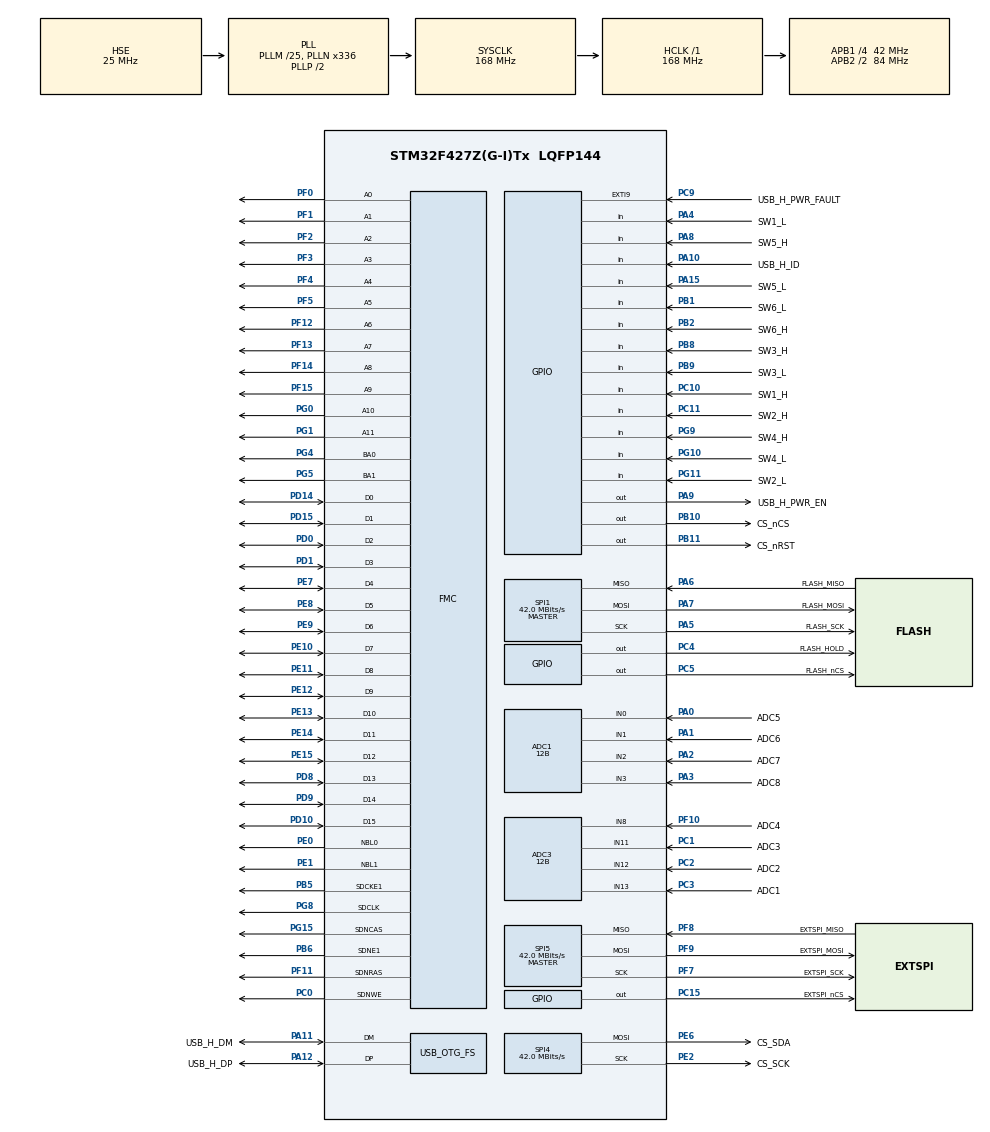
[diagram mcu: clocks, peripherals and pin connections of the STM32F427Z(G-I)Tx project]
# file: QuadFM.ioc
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ADC1.Channel-0\#ChannelRegularConversion=ADC_CHANNEL_0
ADC1.ClockPrescaler=ADC_CLOCK_SYNC_PCLK_DIV8
ADC1.ContinuousConvMode=DISABLE
ADC1.DMAContinuousRequests=DISABLE
ADC1.DataAlign=ADC_DATAALIGN_RIGHT
ADC1.DiscontinuousConvMode=DISABLE
ADC1.EOCSelection=ADC_EOC_SINGLE_CONV
ADC1.EnableAnalogWatchDog=false
ADC1.ExternalTrigConv=ADC_SOFTWARE_START
ADC1.ExternalTrigConvEdge=ADC_EXTERNALTRIGCONVEDGE_NONE
ADC1.InjNumberOfConversion=0
ADC1.NbrOfConversion=1
ADC1.NbrOfConversionFlag=1
ADC1.Rank-0\#ChannelRegularConversion=1
ADC1.Resolution=ADC_RESOLUTION_12B
ADC1.SamplingTime-0\#ChannelRegularConversion=ADC_SAMPLETIME_3CYCLES
ADC1.ScanConvMode=DISABLE
ADC1.master=1
ADC3.Channel-31\#ChannelRegularConversion=ADC_CHANNEL_12
ADC3.Channel-32\#ChannelRegularConversion=ADC_CHANNEL_8
ADC3.Channel-33\#ChannelRegularConversion=ADC_CHANNEL_11
ADC3.Channel-34\#ChannelRegularConversion=ADC_CHANNEL_13
ADC3.ClockPrescaler=ADC_CLOCK_SYNC_PCLK_DIV8
ADC3.ContinuousConvMode=ENABLE
ADC3.DMAContinuousRequests=ENABLE
ADC3.DataAlign=ADC_DATAALIGN_RIGHT
ADC3.DiscontinuousConvMode=DISABLE
ADC3.EOCSelection=ADC_EOC_SEQ_CONV
ADC3.EnableAnalogWatchDog=false
ADC3.ExternalTrigConv=ADC_SOFTWARE_START
ADC3.ExternalTrigConvEdge=ADC_EXTERNALTRIGCONVEDGE_NONE
ADC3.InjNumberOfConversion=0
ADC3.NbrOfConversion=4
ADC3.NbrOfConversionFlag=1
ADC3.Rank-31\#ChannelRegularConversion=1
ADC3.Rank-32\#ChannelRegularConversion=2
ADC3.Rank-33\#ChannelRegularConversion=3
ADC3.Rank-34\#ChannelRegularConversion=4
ADC3.Resolution=ADC_RESOLUTION_12B
ADC3.SamplingTime-31\#ChannelRegularConversion=ADC_SAMPLETIME_144CYCLES
ADC3.SamplingTime-32\#ChannelRegularConversion=ADC_SAMPLETIME_144CYCLES
ADC3.SamplingTime-33\#ChannelRegularConversion=ADC_SAMPLETIME_144CYCLES
ADC3.SamplingTime-34\#ChannelRegularConversion=ADC_SAMPLETIME_144CYCLES
ADC3.ScanConvMode=ENABLE
Dma.ADC1.0.Direction=DMA_PERIPH_TO_MEMORY
Dma.ADC1.0.FIFOMode=DMA_FIFOMODE_DISABLE
Dma.ADC1.0.Instance=DMA2_Stream4
Dma.ADC1.0.MemDataAlignment=DMA_MDATAALIGN_HALFWORD
Dma.ADC1.0.MemInc=DMA_MINC_ENABLE
Dma.ADC1.0.Mode=DMA_NORMAL
Dma.ADC1.0.PeriphDataAlignment=DMA_PDATAALIGN_HALFWORD
Dma.ADC1.0.PeriphInc=DMA_PINC_DISABLE
Dma.ADC1.0.Priority=DMA_PRIORITY_LOW
Dma.ADC3.1.Direction=DMA_PERIPH_TO_MEMORY
Dma.ADC3.1.FIFOMode=DMA_FIFOMODE_DISABLE
Dma.ADC3.1.Instance=DMA2_Stream0
Dma.ADC3.1.MemDataAlignment=DMA_MDATAALIGN_HALFWORD
Dma.ADC3.1.MemInc=DMA_MINC_ENABLE
Dma.ADC3.1.Mode=DMA_CIRCULAR
Dma.ADC3.1.PeriphDataAlignment=DMA_PDATAALIGN_HALFWORD
Dma.ADC3.1.PeriphInc=DMA_PINC_DISABLE
Dma.ADC3.1.Priority=DMA_PRIORITY_LOW
Dma.Request0=ADC1
Dma.Request1=ADC3
FMC.CASLatency1=FMC_SDRAM_CAS_LATENCY_3
FMC.ExitSelfRefreshDelay1=6
FMC.LoadToActiveDelay1=2
FMC.RCDDelay1=2
FMC.RPDelay1=2
FMC.RPDelay2=2
FMC.ReadBurst1=FMC_SDRAM_RBURST_ENABLE
FMC.ReadBurst2=FMC_SDRAM_RBURST_ENABLE
FMC.ReadPipeDelay1=FMC_SDRAM_RPIPE_DELAY_0
FMC.RowCycleDelay1=6
FMC.RowCycleDelay2=6
FMC.SDClockPeriod1=FMC_SDRAM_CLOCK_PERIOD_2
FMC.SDClockPeriod2=FMC_SDRAM_CLOCK_PERIOD_2
FMC.SelfRefreshTime1=4
FMC.WriteRecoveryTime1=2
Mcu.Family=STM32F4
Mcu.Name=STM32F427Z(G-I)Tx
Mcu.Package=LQFP144
NVIC.DMA2_Stream0_IRQn=true\:0\:0\:true\:false\:true\:true
NVIC.DMA2_Stream4_IRQn=true\:5\:0\:true\:false\:true\:true
NVIC.EXTI9_5_IRQn=true\:0\:0\:false\:false\:true\:true
NVIC.OTG_FS_IRQn=true\:0\:0\:false\:false\:true\:true
NVIC.PriorityGroup=NVIC_PRIORITYGROUP_4
PA0/WKUP.GPIO_Label=ADC5
PA0/WKUP.Signal=ADCx_IN0
PA1.GPIO_Label=ADC6
PA1.Signal=ADCx_IN1
PA10.GPIO_Label=USB_H_ID
PA10.GPIO_PuPd=GPIO_PULLUP
PA10.Signal=GPIO_Input
PA11.GPIO_Label=USB_H_DM
PA11.Mode=Host_Only
PA11.Signal=USB_OTG_FS_DM
PA12.GPIO_Label=USB_H_DP
PA12.Mode=Host_Only
PA12.Signal=USB_OTG_FS_DP
PA13.Mode=Trace_Asynchronous_SW
PA13.Signal=SYS_JTMS-SWDIO
PA14.Mode=Trace_Asynchronous_SW
PA14.Signal=SYS_JTCK-SWCLK
PA15.GPIO_Label=SW5_L
PA15.GPIO_Mode=GPIO_MODE_INPUT
PA15.GPIO_PuPd=GPIO_PULLUP
PA15.Signal=GPIO_Input
PA2.GPIO_Label=ADC7
PA2.Signal=ADCx_IN2
PA3.GPIO_Label=ADC8
PA3.Signal=ADCx_IN3
PA4.GPIO_Label=SW1_L
PA4.GPIO_Mode=GPIO_MODE_INPUT
PA4.GPIO_PuPd=GPIO_PULLUP
PA4.Signal=GPIO_Input
PA5.GPIO_Label=FLASH_SCK
PA5.Mode=Full_Duplex_Master
PA5.Signal=SPI1_SCK
PA6.GPIO_Label=FLASH_MISO
PA6.Mode=Full_Duplex_Master
PA6.Signal=SPI1_MISO
PA7.GPIO_Label=FLASH_MOSI
PA7.Mode=Full_Duplex_Master
PA7.Signal=SPI1_MOSI
PA8.GPIO_Label=SW5_H
PA8.GPIO_Mode=GPIO_MODE_INPUT
PA8.GPIO_PuPd=GPIO_PULLUP
PA8.Signal=GPIO_Input
PA9.GPIO_Label=USB_H_PWR_EN
PA9.PinState=GPIO_PIN_SET
PA9.Signal=GPIO_Output
PB1.GPIO_Label=SW6_L
PB1.GPIO_PuPd=GPIO_PULLUP
PB1.Signal=GPIO_Input
PB10.GPIO_Label=CS_nCS
PB10.Signal=GPIO_Output
PB11.GPIO_Label=CS_nRST
PB11.Signal=GPIO_Output
PB2/BOOT1.GPIO_Label=SW6_H
PB2/BOOT1.GPIO_PuPd=GPIO_PULLUP
PB2/BOOT1.Signal=GPIO_Input
PB3.Mode=Trace_Asynchronous_SW
PB3.Signal=SYS_JTDO-SWO
PB5.Mode=SdramChipSelect2_1
PB5.Signal=FMC_SDCKE1
PB6.Mode=SdramChipSelect2_1
PB6.Signal=FMC_SDNE1
PB8.GPIO_Label=SW3_H
PB8.GPIO_Mode=GPIO_MODE_INPUT
PB8.GPIO_PuPd=GPIO_PULLUP
PB8.Signal=GPIO_Input
PB9.GPIO_Label=SW3_L
PB9.GPIO_Mode=GPIO_MODE_INPUT
PB9.GPIO_PuPd=GPIO_PULLUP
PB9.Signal=GPIO_Input
PC0.Signal=FMC_SDNWE
PC1.GPIO_Label=ADC3
PC1.Signal=ADCx_IN11
PC10.GPIO_Label=SW1_H
PC10.GPIO_Mode=GPIO_MODE_INPUT
PC10.GPIO_PuPd=GPIO_PULLUP
PC10.Signal=GPIO_Input
PC11.GPIO_Label=SW2_H
PC11.GPIO_Mode=GPIO_MODE_INPUT
PC11.GPIO_PuPd=GPIO_PULLUP
PC11.Signal=GPIO_Input
PC15/OSC32_OUT.GPIO_Label=EXTSPI_nCS
PC15/OSC32_OUT.Signal=GPIO_Output
PC2.GPIO_Label=ADC2
PC2.Signal=ADCx_IN12
PC3.GPIO_Label=ADC1
PC3.Signal=ADCx_IN13
PC4.GPIO_Label=FLASH_HOLD
PC4.Signal=GPIO_Output
PC5.GPIO_Label=FLASH_nCS
PC5.Signal=GPIO_Output
PC9.GPIO_Label=USB_H_PWR_FAULT
PC9.GPIO_ModeDefaultEXTI=GPIO_MODE_IT_FALLING
PC9.GPIO_PuPd=GPIO_PULLUP
PC9.Signal=GPXTI9
PD0.Signal=FMC_D2_DA2
PD1.Signal=FMC_D3_DA3
PD10.Signal=FMC_D15_DA15
PD14.Signal=FMC_D0_DA0
PD15.Signal=FMC_D1_DA1
PD8.Signal=FMC_D13_DA13
PD9.Signal=FMC_D14_DA14
PE0.Signal=FMC_NBL0
PE1.Signal=FMC_NBL1
PE10.Signal=FMC_D7_DA7
PE11.Signal=FMC_D8_DA8
PE12.Signal=FMC_D9_DA9
PE13.Signal=FMC_D10_DA10
PE14.Signal=FMC_D11_DA11
PE15.Signal=FMC_D12_DA12
PE2.GPIO_Label=CS_SCK
PE2.Mode=TX_Only_Simplex_Unidirect_Master
PE2.Signal=SPI4_SCK
PE6.GPIO_Label=CS_SDA
PE6.Mode=TX_Only_Simplex_Unidirect_Master
PE6.Signal=SPI4_MOSI
PE7.Signal=FMC_D4_DA4
PE8.Signal=FMC_D5_DA5
PE9.Signal=FMC_D6_DA6
PF0.Signal=FMC_A0
PF1.Signal=FMC_A1
PF10.GPIO_Label=ADC4
PF10.Mode=IN8
PF10.Signal=ADC3_IN8
PF11.Signal=FMC_SDNRAS
PF12.Signal=FMC_A6
PF13.Signal=FMC_A7
PF14.Signal=FMC_A8
PF15.Signal=FMC_A9
PF2.Signal=FMC_A2
PF3.Signal=FMC_A3
PF4.Signal=FMC_A4
PF5.Signal=FMC_A5
PF7.GPIO_Label=EXTSPI_SCK
PF7.Mode=Full_Duplex_Master
PF7.Signal=SPI5_SCK
PF8.GPIO_Label=EXTSPI_MISO
PF8.Mode=Full_Duplex_Master
PF8.Signal=SPI5_MISO
PF9.GPIO_Label=EXTSPI_MOSI
PF9.Mode=Full_Duplex_Master
PF9.Signal=SPI5_MOSI
PG0.Signal=FMC_A10
PG1.Signal=FMC_A11
PG10.GPIO_Label=SW4_L
PG10.GPIO_Mode=GPIO_MODE_INPUT
PG10.GPIO_PuPd=GPIO_PULLUP
PG10.Signal=GPIO_Input
PG11.GPIO_Label=SW2_L
PG11.GPIO_Mode=GPIO_MODE_INPUT
PG11.GPIO_PuPd=GPIO_PULLUP
PG11.Signal=GPIO_Input
PG15.Signal=FMC_SDNCAS
PG4.Signal=FMC_A14_BA0
PG5.Signal=FMC_A15_BA1
PG8.Signal=FMC_SDCLK
PG9.GPIO_Label=SW4_H
PG9.GPIO_Mode=GPIO_MODE_INPUT
PG9.GPIO_PuPd=GPIO_PULLUP
PG9.Signal=GPIO_Input
PH0/OSC_IN.Mode=HSE-External-Oscillator
PH0/OSC_IN.Signal=RCC_OSC_IN
PH1/OSC_OUT.Mode=HSE-External-Oscillator
PH1/OSC_OUT.Signal=RCC_OSC_OUT
ProjectManager.HeapSize=0x200
ProjectManager.StackSize=0x400
ProjectManager.TargetToolchain=MDK-ARM V5
RCC.48MHZClocksFreq_Value=48000000
RCC.AHBFreq_Value=168000000
RCC.APB1CLKDivider=RCC_HCLK_DIV4
RCC.APB1Freq_Value=42000000
RCC.APB1TimFreq_Value=84000000
RCC.APB2CLKDivider=RCC_HCLK_DIV2
RCC.APB2Freq_Value=84000000
RCC.APB2TimFreq_Value=168000000
RCC.CortexFreq_Value=168000000
RCC.HCLKFreq_Value=168000000
RCC.HSE_VALUE=25000000
RCC.HSI_VALUE=16000000
RCC.LSE_VALUE=32768
RCC.PLLM=25
RCC.PLLN=336
RCC.PLLQ=7
RCC.PLLSAIN=100
RCC.SYSCLKFreq_VALUE=168000000
RCC.SYSCLKSource=RCC_SYSCLKSOURCE_PLLCLK
RCC.USBFreq_Value=48000000
RCC.VCOOutputFreq_Value=336000000
SH.ADCx_IN0.0=ADC1_IN0,IN0
SH.ADCx_IN1.0=ADC1_IN1,IN1
SH.ADCx_IN11.0=ADC3_IN11,IN11
SH.ADCx_IN12.0=ADC3_IN12,IN12
SH.ADCx_IN13.0=ADC3_IN13,IN13
SH.ADCx_IN2.0=ADC1_IN2,IN2
SH.ADCx_IN3.0=ADC1_IN3,IN3
SH.FMC_A0.0=FMC_A0,12b-sda1
SH.FMC_A1.0=FMC_A1,12b-sda1
SH.FMC_A10.0=FMC_A10,12b-sda1
SH.FMC_A11.0=FMC_A11,12b-sda1
SH.FMC_A14_BA0.0=FMC_BA0,FourSdramBanks1
SH.FMC_A15_BA1.0=FMC_BA1,FourSdramBanks1
SH.FMC_A2.0=FMC_A2,12b-sda1
SH.FMC_A3.0=FMC_A3,12b-sda1
SH.FMC_A4.0=FMC_A4,12b-sda1
SH.FMC_A5.0=FMC_A5,12b-sda1
SH.FMC_A6.0=FMC_A6,12b-sda1
SH.FMC_A7.0=FMC_A7,12b-sda1
SH.FMC_A8.0=FMC_A8,12b-sda1
SH.FMC_A9.0=FMC_A9,12b-sda1
SH.FMC_D0_DA0.0=FMC_D0,sd-16b-d1
SH.FMC_D10_DA10.0=FMC_D10,sd-16b-d1
SH.FMC_D11_DA11.0=FMC_D11,sd-16b-d1
SH.FMC_D12_DA12.0=FMC_D12,sd-16b-d1
SH.FMC_D13_DA13.0=FMC_D13,sd-16b-d1
SH.FMC_D14_DA14.0=FMC_D14,sd-16b-d1
SH.FMC_D15_DA15.0=FMC_D15,sd-16b-d1
SH.FMC_D1_DA1.0=FMC_D1,sd-16b-d1
SH.FMC_D2_DA2.0=FMC_D2,sd-16b-d1
SH.FMC_D3_DA3.0=FMC_D3,sd-16b-d1
SH.FMC_D4_DA4.0=FMC_D4,sd-16b-d1
SH.FMC_D5_DA5.0=FMC_D5,sd-16b-d1
SH.FMC_D6_DA6.0=FMC_D6,sd-16b-d1
SH.FMC_D7_DA7.0=FMC_D7,sd-16b-d1
SH.FMC_D8_DA8.0=FMC_D8,sd-16b-d1
SH.FMC_D9_DA9.0=FMC_D9,sd-16b-d1
SH.FMC_NBL0.0=FMC_NBL0,Sd2ByteEnable1
SH.FMC_NBL1.0=FMC_NBL1,Sd2ByteEnable1
SH.FMC_SDCLK.0=FMC_SDCLK,12b-sda1
SH.FMC_SDNCAS.0=FMC_SDNCAS,12b-sda1
SH.FMC_SDNRAS.0=FMC_SDNRAS,12b-sda1
SH.FMC_SDNWE.0=FMC_SDNWE,12b-sda1
SPI1.CalculateBaudRate=42.0 MBits/s
SPI1.Direction=SPI_DIRECTION_2LINES
SPI1.Mode=SPI_MODE_MASTER
SPI1.VirtualType=VM_MASTER
SPI4.CalculateBaudRate=42.0 MBits/s
SPI4.Direction=SPI_DIRECTION_2LINES
SPI4.Mode=SPI_MODE_MASTER
SPI4.VirtualType=VM_MASTER
SPI5.CalculateBaudRate=42.0 MBits/s
SPI5.Direction=SPI_DIRECTION_2LINES
SPI5.Mode=SPI_MODE_MASTER
SPI5.VirtualType=VM_MASTER
USB_HOST.USBH_HandleTypeDef-AUDIO_FS=hUsbHostFS
USB_HOST.VirtualModeFS=Audio
USB_OTG_FS.VirtualMode=Host_Only
USB_OTG_FS.phy_itface=HCD_PHY_EMBEDDED
VP_USB_HOST_VS_USB_HOST_AUDIO_FS.Mode=AUDIO_FS
board=QuadFM

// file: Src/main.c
/**
  ******************************************************************************
  * File Name          : main.c
  * Description        : Main program body
  ******************************************************************************
  * This notice applies to any and all portions of this file
  * that are not between comment pairs USER CODE BEGIN and
  * USER CODE END. Other portions of this file, whether
  * inserted by the user or by software development tools
  * are owned by their respective copyright owners.
  *
  * Copyright (c) 2017 STMicroelectronics International N.V.
  * All rights reserved.
  *
  * Redistribution and use in source and binary forms, with or without
  * modification, are permitted, provided that the following conditions are met:
  *
  * 1. Redistribution of source code must retain the above copyright notice,
  *    this list of conditions and the following disclaimer.
  * 2. Redistributions in binary form must reproduce the above copyright notice,
  *    this list of conditions and the following disclaimer in the documentation
  *    and/or other materials provided with the distribution.
  * 3. Neither the name of STMicroelectronics nor the names of other
  *    contributors to this software may be used to endorse or promote products
  *    derived from this software without specific written permission.
  * 4. This software, including modifications and/or derivative works of this
  *    software, must execute solely and exclusively on microcontroller or
  *    microprocessor devices manufactured by or for STMicroelectronics.
  * 5. Redistribution and use of this software other than as permitted under
  *    this license is void and will automatically terminate your rights under
  *    this license.
  *
  * THIS SOFTWARE IS PROVIDED BY STMICROELECTRONICS AND CONTRIBUTORS "AS IS"
  * AND ANY EXPRESS, IMPLIED OR STATUTORY WARRANTIES, INCLUDING, BUT NOT
  * LIMITED TO, THE IMPLIED WARRANTIES OF MERCHANTABILITY, FITNESS FOR A
  * PARTICULAR PURPOSE AND NON-INFRINGEMENT OF THIRD PARTY INTELLECTUAL PROPERTY
  * RIGHTS ARE DISCLAIMED TO THE FULLEST EXTENT PERMITTED BY LAW. IN NO EVENT
  * SHALL STMICROELECTRONICS OR CONTRIBUTORS BE LIABLE FOR ANY DIRECT, INDIRECT,
  * INCIDENTAL, SPECIAL, EXEMPLARY, OR CONSEQUENTIAL DAMAGES (INCLUDING, BUT NOT
  * LIMITED TO, PROCUREMENT OF SUBSTITUTE GOODS OR SERVICES; LOSS OF USE, DATA,
  * OR PROFITS; OR BUSINESS INTERRUPTION) HOWEVER CAUSED AND ON ANY THEORY OF
  * LIABILITY, WHETHER IN CONTRACT, STRICT LIABILITY, OR TORT (INCLUDING
  * NEGLIGENCE OR OTHERWISE) ARISING IN ANY WAY OUT OF THE USE OF THIS SOFTWARE,
  * EVEN IF ADVISED OF THE POSSIBILITY OF SUCH DAMAGE.
  *
  ******************************************************************************
  */
#include "main.h"
#include "stm32f4xx_hal.h"
#include "usb_host.h"

/* USER CODE BEGIN Includes */

#include "HAL_ToggleSwitches.h"
#include "TLC5971.h"

/* USER CODE END Includes */

ADC_HandleTypeDef hadc1;
ADC_HandleTypeDef hadc3;
DMA_HandleTypeDef hdma_adc1;
DMA_HandleTypeDef hdma_adc3;

SPI_HandleTypeDef hspi1;
SPI_HandleTypeDef hspi4;
SPI_HandleTypeDef hspi5;

SDRAM_HandleTypeDef hsdram1;

/* USER CODE BEGIN PV */
/* Private variables ---------------------------------------------------------*/

/* USER CODE END PV */

void SystemClock_Config(void);
static void MX_GPIO_Init(void);
static void MX_DMA_Init(void);
static void MX_ADC3_Init(void);
static void MX_FMC_Init(void);
static void MX_SPI5_Init(void);
static void MX_ADC1_Init(void);
static void MX_SPI1_Init(void);
static void MX_SPI4_Init(void);
void MX_USB_HOST_Process(void);

/* USER CODE BEGIN PFP */
/* Private function prototypes -----------------------------------------------*/

/* USER CODE END PFP */

int main(void)
{

  /* MCU Configuration----------------------------------------------------------*/

  /* Reset of all peripherals, Initializes the Flash interface and the Systick. */
  HAL_Init();

  /* Configure the system clock */
  SystemClock_Config();

  /* Initialize all configured peripherals */
  MX_GPIO_Init();
  MX_DMA_Init();
  MX_ADC3_Init();
  MX_FMC_Init();
  MX_SPI5_Init();
  MX_ADC1_Init();
  MX_SPI1_Init();
  MX_SPI4_Init();
  MX_USB_HOST_Init();

  /* USER CODE BEGIN 2 */
	TLC5971_init(&hspi5);

	TLC5971_SetOutput_GS(LED_A, LED_Red, 	0xFFFF);
//	TLC5971_SetOutput_GS(LED_A, LED_Green,0xFFFF);
//	TLC5971_SetOutput_GS(LED_A, LED_Blue, 0xFFFF);

//	TLC5971_SetOutput_GS(LED_B, LED_Red, 	0xFFFF);
	TLC5971_SetOutput_GS(LED_B, LED_Green,0xFFFF);
//	TLC5971_SetOutput_GS(LED_B, LED_Blue, 0xFFFF);

//	TLC5971_SetOutput_GS(LED_C, LED_Red, 	0xFFFF);
//	TLC5971_SetOutput_GS(LED_C, LED_Green,0xFFFF);
	TLC5971_SetOutput_GS(LED_C, LED_Blue, 0xFFFF);

	TLC5971_SetOutput_GS(LED_D, LED_Red, 	0xFFFF);
	TLC5971_SetOutput_GS(LED_D, LED_Green,0xFFFF);
	TLC5971_SetOutput_GS(LED_D, LED_Blue, 0xFFFF);

	TLC5971_SetOutput_BC(LED_Red, 	 0x08);
	TLC5971_SetOutput_BC(LED_Green,  0x02);
	TLC5971_SetOutput_BC(LED_Blue,   0x05);

	TLC5971_Settings(REG_DSRPT);
	TLC5971_Update();

//	HAL_GPIO_WritePin(USB_H_PWR_EN_GPIO_Port, USB_H_PWR_EN_Pin, GPIO_PIN_RESET);

  /* USER CODE END 2 */

  /* Infinite loop */
  /* USER CODE BEGIN WHILE */
  while (1)
  {
		uint32_t delay = 1000000;
		while(--delay){}

		HAL_Toggles_Scan();

  /* USER CODE END WHILE */
    MX_USB_HOST_Process();

  }

}

/** System Clock Configuration
*/
void SystemClock_Config(void)
{

  RCC_OscInitTypeDef RCC_OscInitStruct;
  RCC_ClkInitTypeDef RCC_ClkInitStruct;

    /**Configure the main internal regulator output voltage
    */
  __HAL_RCC_PWR_CLK_ENABLE();

  __HAL_PWR_VOLTAGESCALING_CONFIG(PWR_REGULATOR_VOLTAGE_SCALE1);

    /**Initializes the CPU, AHB and APB busses clocks
    */
  RCC_OscInitStruct.OscillatorType = RCC_OSCILLATORTYPE_HSE;
  RCC_OscInitStruct.HSEState = RCC_HSE_ON;
  RCC_OscInitStruct.PLL.PLLState = RCC_PLL_ON;
  RCC_OscInitStruct.PLL.PLLSource = RCC_PLLSOURCE_HSE;
  RCC_OscInitStruct.PLL.PLLM = 25;
  RCC_OscInitStruct.PLL.PLLN = 336;
  RCC_OscInitStruct.PLL.PLLP = RCC_PLLP_DIV2;
  RCC_OscInitStruct.PLL.PLLQ = 7;
  if (HAL_RCC_OscConfig(&RCC_OscInitStruct) != HAL_OK)
  {
    _Error_Handler(__FILE__, __LINE__);
  }

    /**Initializes the CPU, AHB and APB busses clocks
    */
  RCC_ClkInitStruct.ClockType = RCC_CLOCKTYPE_HCLK|RCC_CLOCKTYPE_SYSCLK
                              |RCC_CLOCKTYPE_PCLK1|RCC_CLOCKTYPE_PCLK2;
  RCC_ClkInitStruct.SYSCLKSource = RCC_SYSCLKSOURCE_PLLCLK;
  RCC_ClkInitStruct.AHBCLKDivider = RCC_SYSCLK_DIV1;
  RCC_ClkInitStruct.APB1CLKDivider = RCC_HCLK_DIV4;
  RCC_ClkInitStruct.APB2CLKDivider = RCC_HCLK_DIV2;

  if (HAL_RCC_ClockConfig(&RCC_ClkInitStruct, FLASH_LATENCY_5) != HAL_OK)
  {
    _Error_Handler(__FILE__, __LINE__);
  }

    /**Configure the Systick interrupt time
    */
  HAL_SYSTICK_Config(HAL_RCC_GetHCLKFreq()/1000);

    /**Configure the Systick
    */
  HAL_SYSTICK_CLKSourceConfig(SYSTICK_CLKSOURCE_HCLK);

  /* SysTick_IRQn interrupt configuration */
  HAL_NVIC_SetPriority(SysTick_IRQn, 0, 0);
}

/* ADC1 init function */
static void MX_ADC1_Init(void)
{

  ADC_ChannelConfTypeDef sConfig;

    /**Configure the global features of the ADC (Clock, Resolution, Data Alignment and number of conversion)
    */
  hadc1.Instance = ADC1;
  hadc1.Init.ClockPrescaler = ADC_CLOCK_SYNC_PCLK_DIV8;
  hadc1.Init.Resolution = ADC_RESOLUTION_12B;
  hadc1.Init.ScanConvMode = DISABLE;
  hadc1.Init.ContinuousConvMode = DISABLE;
  hadc1.Init.DiscontinuousConvMode = DISABLE;
  hadc1.Init.ExternalTrigConvEdge = ADC_EXTERNALTRIGCONVEDGE_NONE;
  hadc1.Init.ExternalTrigConv = ADC_SOFTWARE_START;
  hadc1.Init.DataAlign = ADC_DATAALIGN_RIGHT;
  hadc1.Init.NbrOfConversion = 1;
  hadc1.Init.DMAContinuousRequests = DISABLE;
  hadc1.Init.EOCSelection = ADC_EOC_SINGLE_CONV;
  if (HAL_ADC_Init(&hadc1) != HAL_OK)
  {
    _Error_Handler(__FILE__, __LINE__);
  }

    /**Configure for the selected ADC regular channel its corresponding rank in the sequencer and its sample time.
    */
  sConfig.Channel = ADC_CHANNEL_0;
  sConfig.Rank = 1;
  sConfig.SamplingTime = ADC_SAMPLETIME_3CYCLES;
  if (HAL_ADC_ConfigChannel(&hadc1, &sConfig) != HAL_OK)
  {
    _Error_Handler(__FILE__, __LINE__);
  }

}

/* ADC3 init function */
static void MX_ADC3_Init(void)
{

  ADC_ChannelConfTypeDef sConfig;

    /**Configure the global features of the ADC (Clock, Resolution, Data Alignment and number of conversion)
    */
  hadc3.Instance = ADC3;
  hadc3.Init.ClockPrescaler = ADC_CLOCK_SYNC_PCLK_DIV8;
  hadc3.Init.Resolution = ADC_RESOLUTION_12B;
  hadc3.Init.ScanConvMode = ENABLE;
  hadc3.Init.ContinuousConvMode = ENABLE;
  hadc3.Init.DiscontinuousConvMode = DISABLE;
  hadc3.Init.ExternalTrigConvEdge = ADC_EXTERNALTRIGCONVEDGE_NONE;
  hadc3.Init.ExternalTrigConv = ADC_SOFTWARE_START;
  hadc3.Init.DataAlign = ADC_DATAALIGN_RIGHT;
  hadc3.Init.NbrOfConversion = 4;
  hadc3.Init.DMAContinuousRequests = ENABLE;
  hadc3.Init.EOCSelection = ADC_EOC_SEQ_CONV;
  if (HAL_ADC_Init(&hadc3) != HAL_OK)
  {
    _Error_Handler(__FILE__, __LINE__);
  }

    /**Configure for the selected ADC regular channel its corresponding rank in the sequencer and its sample time.
    */
  sConfig.Channel = ADC_CHANNEL_12;
  sConfig.Rank = 1;
  sConfig.SamplingTime = ADC_SAMPLETIME_144CYCLES;
  if (HAL_ADC_ConfigChannel(&hadc3, &sConfig) != HAL_OK)
  {
    _Error_Handler(__FILE__, __LINE__);
  }

    /**Configure for the selected ADC regular channel its corresponding rank in the sequencer and its sample time.
    */
  sConfig.Channel = ADC_CHANNEL_8;
  sConfig.Rank = 2;
  if (HAL_ADC_ConfigChannel(&hadc3, &sConfig) != HAL_OK)
  {
    _Error_Handler(__FILE__, __LINE__);
  }

    /**Configure for the selected ADC regular channel its corresponding rank in the sequencer and its sample time.
    */
  sConfig.Channel = ADC_CHANNEL_11;
  sConfig.Rank = 3;
  if (HAL_ADC_ConfigChannel(&hadc3, &sConfig) != HAL_OK)
  {
    _Error_Handler(__FILE__, __LINE__);
  }

    /**Configure for the selected ADC regular channel its corresponding rank in the sequencer and its sample time.
    */
  sConfig.Channel = ADC_CHANNEL_13;
  sConfig.Rank = 4;
  if (HAL_ADC_ConfigChannel(&hadc3, &sConfig) != HAL_OK)
  {
    _Error_Handler(__FILE__, __LINE__);
  }

}

/* SPI1 init function */
static void MX_SPI1_Init(void)
{

  hspi1.Instance = SPI1;
  hspi1.Init.Mode = SPI_MODE_MASTER;
  hspi1.Init.Direction = SPI_DIRECTION_2LINES;
  hspi1.Init.DataSize = SPI_DATASIZE_8BIT;
  hspi1.Init.CLKPolarity = SPI_POLARITY_LOW;
  hspi1.Init.CLKPhase = SPI_PHASE_1EDGE;
  hspi1.Init.NSS = SPI_NSS_SOFT;
  hspi1.Init.BaudRatePrescaler = SPI_BAUDRATEPRESCALER_2;
  hspi1.Init.FirstBit = SPI_FIRSTBIT_MSB;
  hspi1.Init.TIMode = SPI_TIMODE_DISABLE;
  hspi1.Init.CRCCalculation = SPI_CRCCALCULATION_DISABLE;
  hspi1.Init.CRCPolynomial = 10;
  if (HAL_SPI_Init(&hspi1) != HAL_OK)
  {
    _Error_Handler(__FILE__, __LINE__);
  }

}

/* SPI4 init function */
static void MX_SPI4_Init(void)
{

  hspi4.Instance = SPI4;
  hspi4.Init.Mode = SPI_MODE_MASTER;
  hspi4.Init.Direction = SPI_DIRECTION_2LINES;
  hspi4.Init.DataSize = SPI_DATASIZE_8BIT;
  hspi4.Init.CLKPolarity = SPI_POLARITY_LOW;
  hspi4.Init.CLKPhase = SPI_PHASE_1EDGE;
  hspi4.Init.NSS = SPI_NSS_SOFT;
  hspi4.Init.BaudRatePrescaler = SPI_BAUDRATEPRESCALER_2;
  hspi4.Init.FirstBit = SPI_FIRSTBIT_MSB;
  hspi4.Init.TIMode = SPI_TIMODE_DISABLE;
  hspi4.Init.CRCCalculation = SPI_CRCCALCULATION_DISABLE;
  hspi4.Init.CRCPolynomial = 10;
  if (HAL_SPI_Init(&hspi4) != HAL_OK)
  {
    _Error_Handler(__FILE__, __LINE__);
  }

}

/* SPI5 init function */
static void MX_SPI5_Init(void)
{

  hspi5.Instance = SPI5;
  hspi5.Init.Mode = SPI_MODE_MASTER;
  hspi5.Init.Direction = SPI_DIRECTION_2LINES;
  hspi5.Init.DataSize = SPI_DATASIZE_8BIT;
  hspi5.Init.CLKPolarity = SPI_POLARITY_LOW;
  hspi5.Init.CLKPhase = SPI_PHASE_1EDGE;
  hspi5.Init.NSS = SPI_NSS_SOFT;
  hspi5.Init.BaudRatePrescaler = SPI_BAUDRATEPRESCALER_2;
  hspi5.Init.FirstBit = SPI_FIRSTBIT_MSB;
  hspi5.Init.TIMode = SPI_TIMODE_DISABLE;
  hspi5.Init.CRCCalculation = SPI_CRCCALCULATION_DISABLE;
  hspi5.Init.CRCPolynomial = 10;
  if (HAL_SPI_Init(&hspi5) != HAL_OK)
  {
    _Error_Handler(__FILE__, __LINE__);
  }

}

static void MX_DMA_Init(void)
{
  /* DMA controller clock enable */
  __HAL_RCC_DMA2_CLK_ENABLE();

  /* DMA interrupt init */
  /* DMA2_Stream0_IRQn interrupt configuration */
  HAL_NVIC_SetPriority(DMA2_Stream0_IRQn, 0, 0);
  HAL_NVIC_EnableIRQ(DMA2_Stream0_IRQn);
  /* DMA2_Stream4_IRQn interrupt configuration */
  HAL_NVIC_SetPriority(DMA2_Stream4_IRQn, 5, 0);
  HAL_NVIC_EnableIRQ(DMA2_Stream4_IRQn);

}
/* FMC initialization function */
static void MX_FMC_Init(void)
{
  FMC_SDRAM_TimingTypeDef SdramTiming;

  /** Perform the SDRAM1 memory initialization sequence
  */
  hsdram1.Instance = FMC_SDRAM_DEVICE;
  /* hsdram1.Init */
  hsdram1.Init.SDBank = FMC_SDRAM_BANK2;
  hsdram1.Init.ColumnBitsNumber = FMC_SDRAM_COLUMN_BITS_NUM_8;
  hsdram1.Init.RowBitsNumber = FMC_SDRAM_ROW_BITS_NUM_12;
  hsdram1.Init.MemoryDataWidth = FMC_SDRAM_MEM_BUS_WIDTH_16;
  hsdram1.Init.InternalBankNumber = FMC_SDRAM_INTERN_BANKS_NUM_4;
  hsdram1.Init.CASLatency = FMC_SDRAM_CAS_LATENCY_3;
  hsdram1.Init.WriteProtection = FMC_SDRAM_WRITE_PROTECTION_DISABLE;
  hsdram1.Init.SDClockPeriod = FMC_SDRAM_CLOCK_PERIOD_2;
  hsdram1.Init.ReadBurst = FMC_SDRAM_RBURST_ENABLE;
  hsdram1.Init.ReadPipeDelay = FMC_SDRAM_RPIPE_DELAY_0;
  /* SdramTiming */
  SdramTiming.LoadToActiveDelay = 2;
  SdramTiming.ExitSelfRefreshDelay = 6;
  SdramTiming.SelfRefreshTime = 4;
  SdramTiming.RowCycleDelay = 6;
  SdramTiming.WriteRecoveryTime = 2;
  SdramTiming.RPDelay = 2;
  SdramTiming.RCDDelay = 2;

  if (HAL_SDRAM_Init(&hsdram1, &SdramTiming) != HAL_OK)
  {
    _Error_Handler(__FILE__, __LINE__);
  }

}

/** Configure pins as
        * Analog
        * Input
        * Output
        * EVENT_OUT
        * EXTI
*/
static void MX_GPIO_Init(void)
{

  GPIO_InitTypeDef GPIO_InitStruct;

  /* GPIO Ports Clock Enable */
  __HAL_RCC_GPIOE_CLK_ENABLE();
  __HAL_RCC_GPIOC_CLK_ENABLE();
  __HAL_RCC_GPIOF_CLK_ENABLE();
  __HAL_RCC_GPIOH_CLK_ENABLE();
  __HAL_RCC_GPIOA_CLK_ENABLE();
  __HAL_RCC_GPIOB_CLK_ENABLE();
  __HAL_RCC_GPIOG_CLK_ENABLE();
  __HAL_RCC_GPIOD_CLK_ENABLE();

  /*Configure GPIO pin Output Level */
  HAL_GPIO_WritePin(GPIOC, EXTSPI_nCS_Pin|FLASH_HOLD_Pin|FLASH_nCS_Pin, GPIO_PIN_RESET);

  /*Configure GPIO pin Output Level */
  HAL_GPIO_WritePin(GPIOB, CS_nCS_Pin|CS_nRST_Pin, GPIO_PIN_RESET);

  /*Configure GPIO pin Output Level */
  HAL_GPIO_WritePin(USB_H_PWR_EN_GPIO_Port, USB_H_PWR_EN_Pin, GPIO_PIN_SET);

  /*Configure GPIO pins : EXTSPI_nCS_Pin FLASH_HOLD_Pin FLASH_nCS_Pin */
  GPIO_InitStruct.Pin = EXTSPI_nCS_Pin|FLASH_HOLD_Pin|FLASH_nCS_Pin;
  GPIO_InitStruct.Mode = GPIO_MODE_OUTPUT_PP;
  GPIO_InitStruct.Pull = GPIO_NOPULL;
  GPIO_InitStruct.Speed = GPIO_SPEED_FREQ_LOW;
  HAL_GPIO_Init(GPIOC, &GPIO_InitStruct);

  /*Configure GPIO pins : SW1_L_Pin SW5_H_Pin USB_H_ID_Pin SW5_L_Pin */
  GPIO_InitStruct.Pin = SW1_L_Pin|SW5_H_Pin|USB_H_ID_Pin|SW5_L_Pin;
  GPIO_InitStruct.Mode = GPIO_MODE_INPUT;
  GPIO_InitStruct.Pull = GPIO_PULLUP;
  HAL_GPIO_Init(GPIOA, &GPIO_InitStruct);

  /*Configure GPIO pins : SW6_L_Pin SW6_H_Pin SW3_H_Pin SW3_L_Pin */
  GPIO_InitStruct.Pin = SW6_L_Pin|SW6_H_Pin|SW3_H_Pin|SW3_L_Pin;
  GPIO_InitStruct.Mode = GPIO_MODE_INPUT;
  GPIO_InitStruct.Pull = GPIO_PULLUP;
  HAL_GPIO_Init(GPIOB, &GPIO_InitStruct);

  /*Configure GPIO pins : CS_nCS_Pin CS_nRST_Pin */
  GPIO_InitStruct.Pin = CS_nCS_Pin|CS_nRST_Pin;
  GPIO_InitStruct.Mode = GPIO_MODE_OUTPUT_PP;
  GPIO_InitStruct.Pull = GPIO_NOPULL;
  GPIO_InitStruct.Speed = GPIO_SPEED_FREQ_LOW;
  HAL_GPIO_Init(GPIOB, &GPIO_InitStruct);

  /*Configure GPIO pin : USB_H_PWR_FAULT_Pin */
  GPIO_InitStruct.Pin = USB_H_PWR_FAULT_Pin;
  GPIO_InitStruct.Mode = GPIO_MODE_IT_FALLING;
  GPIO_InitStruct.Pull = GPIO_PULLUP;
  HAL_GPIO_Init(USB_H_PWR_FAULT_GPIO_Port, &GPIO_InitStruct);

  /*Configure GPIO pin : USB_H_PWR_EN_Pin */
  GPIO_InitStruct.Pin = USB_H_PWR_EN_Pin;
  GPIO_InitStruct.Mode = GPIO_MODE_OUTPUT_PP;
  GPIO_InitStruct.Pull = GPIO_NOPULL;
  GPIO_InitStruct.Speed = GPIO_SPEED_FREQ_LOW;
  HAL_GPIO_Init(USB_H_PWR_EN_GPIO_Port, &GPIO_InitStruct);

  /*Configure GPIO pins : SW1_H_Pin SW2_H_Pin */
  GPIO_InitStruct.Pin = SW1_H_Pin|SW2_H_Pin;
  GPIO_InitStruct.Mode = GPIO_MODE_INPUT;
  GPIO_InitStruct.Pull = GPIO_PULLUP;
  HAL_GPIO_Init(GPIOC, &GPIO_InitStruct);

  /*Configure GPIO pins : SW4_H_Pin SW4_L_Pin SW2_L_Pin */
  GPIO_InitStruct.Pin = SW4_H_Pin|SW4_L_Pin|SW2_L_Pin;
  GPIO_InitStruct.Mode = GPIO_MODE_INPUT;
  GPIO_InitStruct.Pull = GPIO_PULLUP;
  HAL_GPIO_Init(GPIOG, &GPIO_InitStruct);

  /* EXTI interrupt init*/
  HAL_NVIC_SetPriority(EXTI9_5_IRQn, 0, 0);
  HAL_NVIC_EnableIRQ(EXTI9_5_IRQn);

}

void _Error_Handler(char * file, int line)
{
  while(1)
  {
  }
}

/************************ (C) COPYRIGHT STMicroelectronics *****END OF FILE****/
